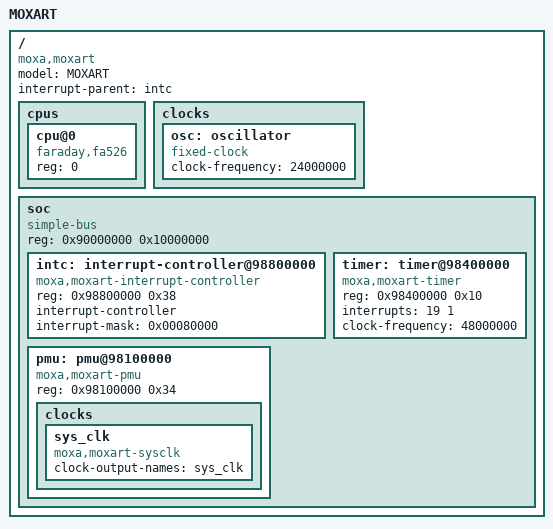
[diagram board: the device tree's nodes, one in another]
/* moxart.dtsi - Device Tree Include file for MOXA ART family SoC
 *
 * Copyright (C) 2013 Jonas Jensen <jonas.jensen@gmail.com>
 *
 * Licensed under GPLv2 or later.
 */

/include/ "skeleton.dtsi"

/ {
	compatible = "moxa,moxart";
	model = "MOXART";
	interrupt-parent = <&intc>;

	cpus {
		#address-cells = <1>;
		#size-cells = <0>;

		cpu@0 {
			device_type = "cpu";
			compatible = "faraday,fa526";
			reg = <0>;
		};
	};

	clocks {
		#address-cells = <1>;
		#size-cells = <0>;

		osc: oscillator {
			#clock-cells = <0>;
			compatible = "fixed-clock";
			clock-frequency = <24000000>;
		};
	};

	soc {
		compatible = "simple-bus";
		#address-cells = <1>;
		#size-cells = <1>;
		reg = <0x90000000 0x10000000>;
		ranges;

		intc: interrupt-controller@98800000 {
			compatible = "moxa,moxart-interrupt-controller";
			reg = <0x98800000 0x38>;
			interrupt-controller;
			#interrupt-cells = <2>;

			/* single register vector, interrupts 0-31, 1s signify edge */
			interrupt-mask = <0x00080000>;
		};

		timer: timer@98400000 {
			compatible = "moxa,moxart-timer";
			reg = <0x98400000 0x10>;
			interrupts = <19 1>;
			clock-frequency = <48000000>;
		};

		/* Power Management Unit */
		pmu: pmu@98100000 {
			compatible = "moxa,moxart-pmu";

			/* offset mul @ 0x30, val @ 0x0c (2 * 32 bit registers) */
			reg = <0x98100000 0x34>;

			clocks {
				sys_clk: sys_clk {
					#clock-cells = <0>;
					compatible = "moxa,moxart-sysclk";
					clock-output-names = "sys_clk";
				};
			};
		};

/*
		clocks {
			apb_clk: apb_clk {
				#clock-cells = <0>;
				compatible = "fixed-clock";
				clock-frequency = <48000000>;
				clock-output-names = "apb_clk";
			};
		};
*/

	};
};
